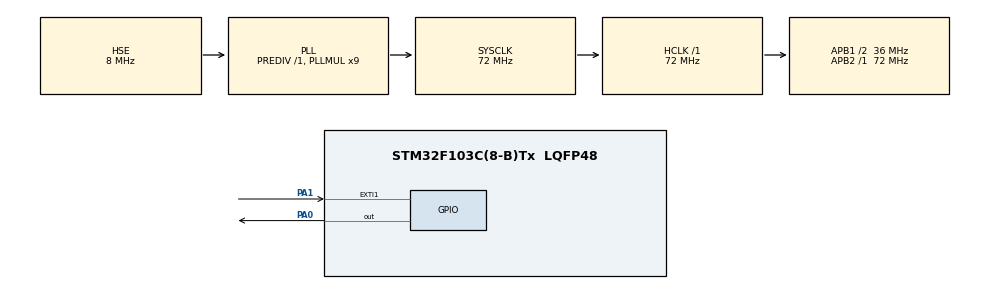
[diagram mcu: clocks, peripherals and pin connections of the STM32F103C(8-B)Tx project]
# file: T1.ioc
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Mcu.Family=STM32F1
Mcu.Name=STM32F103C(8-B)Tx
Mcu.Package=LQFP48
NVIC.EXTI1_IRQn=true\:1\:0\:true\:false\:true\:true\:true\:true
NVIC.PriorityGroup=NVIC_PRIORITYGROUP_4
NVIC.TIM2_IRQn=true\:0\:0\:false\:false\:true\:true\:true\:true
PA0-WKUP.Signal=GPIO_Output
PA1.GPIO_ModeDefaultEXTI=GPIO_MODE_IT_FALLING
PA1.GPIO_PuPd=GPIO_PULLUP
PA1.Signal=GPXTI1
PA13.Mode=Serial_Wire
PA13.Signal=SYS_JTMS-SWDIO
PA14.Mode=Serial_Wire
PA14.Signal=SYS_JTCK-SWCLK
PD0-OSC_IN.Mode=HSE-External-Oscillator
PD0-OSC_IN.Signal=RCC_OSC_IN
PD1-OSC_OUT.Mode=HSE-External-Oscillator
PD1-OSC_OUT.Signal=RCC_OSC_OUT
ProjectManager.HeapSize=0x200
ProjectManager.StackSize=0x400
ProjectManager.TargetToolchain=MDK-ARM V5.32
RCC.AHBFreq_Value=72000000
RCC.APB1CLKDivider=RCC_HCLK_DIV2
RCC.APB1Freq_Value=36000000
RCC.APB1TimFreq_Value=72000000
RCC.APB2Freq_Value=72000000
RCC.APB2TimFreq_Value=72000000
RCC.HCLKFreq_Value=72000000
RCC.PLLMUL=RCC_PLL_MUL9
RCC.PLLSourceVirtual=RCC_PLLSOURCE_HSE
RCC.SYSCLKFreq_VALUE=72000000
RCC.SYSCLKSource=RCC_SYSCLKSOURCE_PLLCLK
RCC.USBFreq_Value=72000000
TIM2.Period=999
TIM2.Prescaler=71
VP_TIM2_VS_ClockSourceINT.Mode=Internal
board=custom

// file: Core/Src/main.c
/* USER CODE BEGIN Header */
/**
  ******************************************************************************
  * @file           : main.c
  * @brief          : Main program body
  ******************************************************************************
  * @attention
  *
  * Copyright (c) 2026 STMicroelectronics.
  * All rights reserved.
  *
  * This software is licensed under terms that can be found in the LICENSE file
  * in the root directory of this software component.
  * If no LICENSE file comes with this software, it is provided AS-IS.
  *
  ******************************************************************************
  */
/* USER CODE END Header */
#include "main.h"
#include "tim.h"
#include "gpio.h"

/* USER CODE BEGIN PV */
uint16_t button=0;	//button:0熄灭 1常亮 2闪烁
uint16_t clean=0;
uint16_t button_time=0;
uint16_t flicker=0;
/* USER CODE END PV */

void SystemClock_Config(void);

int main(void)
{

  /* MCU Configuration--------------------------------------------------------*/

  /* Reset of all peripherals, Initializes the Flash interface and the Systick. */
  HAL_Init();

  /* Configure the system clock */
  SystemClock_Config();

  /* Initialize all configured peripherals */
  MX_GPIO_Init();
  MX_TIM2_Init();
  /* USER CODE BEGIN 2 */
	HAL_TIM_Base_Start_IT(&htim2);
  /* USER CODE END 2 */

  /* Infinite loop */
  while (1)
  {

  }
}

void SystemClock_Config(void)
{
  RCC_OscInitTypeDef RCC_OscInitStruct = {0};
  RCC_ClkInitTypeDef RCC_ClkInitStruct = {0};

  /** Initializes the RCC Oscillators according to the specified parameters
  * in the RCC_OscInitTypeDef structure.
  */
  RCC_OscInitStruct.OscillatorType = RCC_OSCILLATORTYPE_HSE;
  RCC_OscInitStruct.HSEState = RCC_HSE_ON;
  RCC_OscInitStruct.HSEPredivValue = RCC_HSE_PREDIV_DIV1;
  RCC_OscInitStruct.HSIState = RCC_HSI_ON;
  RCC_OscInitStruct.PLL.PLLState = RCC_PLL_ON;
  RCC_OscInitStruct.PLL.PLLSource = RCC_PLLSOURCE_HSE;
  RCC_OscInitStruct.PLL.PLLMUL = RCC_PLL_MUL9;
  if (HAL_RCC_OscConfig(&RCC_OscInitStruct) != HAL_OK)
  {
    Error_Handler();
  }

  /** Initializes the CPU, AHB and APB buses clocks
  */
  RCC_ClkInitStruct.ClockType = RCC_CLOCKTYPE_HCLK|RCC_CLOCKTYPE_SYSCLK
                              |RCC_CLOCKTYPE_PCLK1|RCC_CLOCKTYPE_PCLK2;
  RCC_ClkInitStruct.SYSCLKSource = RCC_SYSCLKSOURCE_PLLCLK;
  RCC_ClkInitStruct.AHBCLKDivider = RCC_SYSCLK_DIV1;
  RCC_ClkInitStruct.APB1CLKDivider = RCC_HCLK_DIV2;
  RCC_ClkInitStruct.APB2CLKDivider = RCC_HCLK_DIV1;

  if (HAL_RCC_ClockConfig(&RCC_ClkInitStruct, FLASH_LATENCY_2) != HAL_OK)
  {
    Error_Handler();
  }
}

/* USER CODE BEGIN 4 */
void HAL_GPIO_EXTI_Callback(uint16_t GPIO_Pin)
{
	if(GPIO_Pin==GPIO_PIN_1)
	{
		clean=1;
	}
}
void HAL_TIM_PeriodElapsedCallback(TIM_HandleTypeDef *htim)
{
	if(htim->Instance==TIM2)
	{
		if(clean==1)	//按键按下中
		{
			if(HAL_GPIO_ReadPin(GPIOA, GPIO_PIN_1)==GPIO_PIN_RESET)
			{
				button_time++;	//累加按住时间
			}
			else if(button_time>20)	//消抖
			{
				clean=0;
				if(button_time<1000)	//短按：常亮
				{
					button=1;
				}
				else if(button==2)	//长按，且本来在闪：熄灭
				{
					button=0;
				}
				else	//长按：闪烁
				{
					button=2;
				}
				button_time=0;
				flicker=0;
			}
		}
		if(button==0)		//熄灭
		{
			HAL_GPIO_WritePin(GPIOA, GPIO_PIN_0, GPIO_PIN_RESET);
		}
		if(button==1)		//常亮
		{
			HAL_GPIO_WritePin(GPIOA, GPIO_PIN_0, GPIO_PIN_SET);
		}
		if(button==2)		//闪烁
		{
			flicker++;
			if(flicker>=100)
			{
				flicker=0;
				HAL_GPIO_TogglePin(GPIOA, GPIO_PIN_0);
			}
		}
	}
}
/* USER CODE END 4 */

void Error_Handler(void)
{
  __disable_irq();
  while (1)
  {
  }
}
